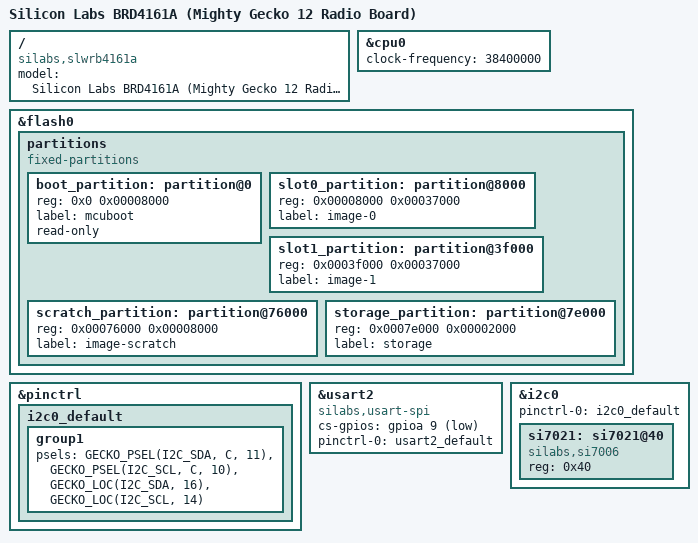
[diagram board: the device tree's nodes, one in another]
/*
 * Copyright (c) 2020 Piotr Mienkowski
 *
 * SPDX-License-Identifier: Apache-2.0
 */

/dts-v1/;
#include <silabs/xg12/efr32mg12p432f1024gl125.dtsi>
#include "../common/efr32-series1-common.dtsi"

/ {
	model = "Silicon Labs BRD4161A (Mighty Gecko 12 Radio Board)";
	compatible = "silabs,slwrb4161a", "silabs,efr32mg12p";
};

&cpu0 {
	clock-frequency = <38400000>;
};

&flash0 {
	partitions {
		compatible = "fixed-partitions";
		#address-cells = <1>;
		#size-cells = <1>;

		/* Reserve 32 kB for the bootloader */
		boot_partition: partition@0 {
			reg = <0x0 0x00008000>;
			label = "mcuboot";
			read-only;
		};

		/* Reserve 220 kB for the application in slot 0 */
		slot0_partition: partition@8000 {
			reg = <0x00008000 0x00037000>;
			label = "image-0";
		};

		/* Reserve 220 kB for the application in slot 1 */
		slot1_partition: partition@3f000 {
			reg = <0x0003f000 0x00037000>;
			label = "image-1";
		};

		/* Reserve 32 kB for the scratch partition */
		scratch_partition: partition@76000 {
			reg = <0x00076000 0x00008000>;
			label = "image-scratch";
		};

		/* Set 8Kb of storage at the end of the 512KB of flash */
		storage_partition: partition@7e000 {
			reg = <0x0007e000 0x00002000>;
			label = "storage";
		};
	};
};

&pinctrl {
	i2c0_default: i2c0_default {
		group1 {
			psels = <GECKO_PSEL(I2C_SDA, C, 11)>,
				<GECKO_PSEL(I2C_SCL, C, 10)>,
				<GECKO_LOC(I2C_SDA, 16)>,
				<GECKO_LOC(I2C_SCL, 14)>;
		};
	};
};

&usart2 {
	compatible = "silabs,usart-spi";
	#address-cells = <1>;
	#size-cells = <0>;
	cs-gpios = <&gpioa 9 GPIO_ACTIVE_LOW>;
	pinctrl-0 = <&usart2_default>;
	pinctrl-names = "default";
	status = "okay";
};

&i2c0 {
	pinctrl-0 = <&i2c0_default>;
	pinctrl-names = "default";
	status = "okay";

	si7021: si7021@40 {
		compatible = "silabs,si7006";
		reg = <0x40>;
	};
};
